# N575F145_v1 register map
File version: 1.0
Registers are 32-bit, read-write, reset 0x0 unless marked. A register's access mark holds for its fields unless they carry their own. Offsets are from the block's base; [hi:lo] are bit positions; 'fields as' and 'values as' point back to an identical list.

## CLK — CLK Register Map
Base 0x50000200
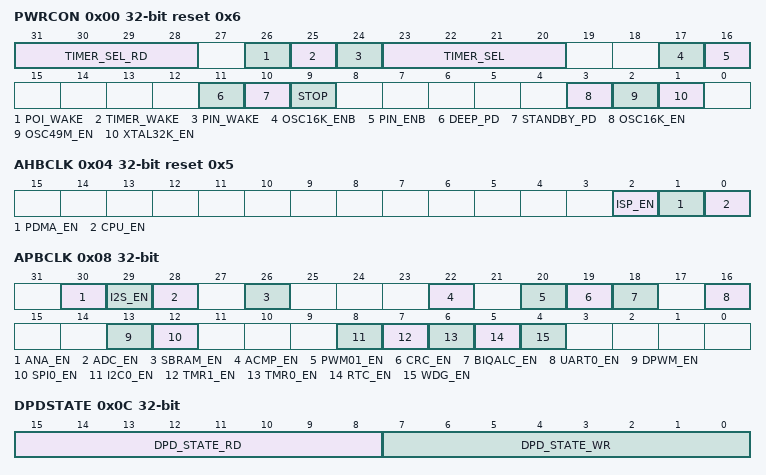
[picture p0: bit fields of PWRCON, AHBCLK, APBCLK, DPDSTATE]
0x00 PWRCON reset 0x6 (reset mask 0xFFFFFF) — System Power Control Register
  [31:28] TIMER_SEL_RD — Current Wakeup Timer Setting. Read-Only. Read back of the current WAKEUP timer setting. This value is updated with TIMER_SEL upon entering DPD mode.
  [26] POI_WAKE — POI Wakeup Flag. Read Only. This flag indicates that wakeup of device was requested with a power-on reset. Flag is cleared when DPD mode is entered.
  [25] TIMER_WAKE — Timer Wakeup Flag. Read Only. This flag indicates that wakeup of device was requested with TIMER count of the 16Khz oscillator. Flag is cleared when DPD mode is entered.
  [24] PIN_WAKE — Pin Wakeup Flag. Read Only. This flag indicates that wakeup of device was requested with a high to low transition of the WAKEUP pin. Flag is cleared when DPD mode is entered.
  [23:20] TIMER_SEL — Select Wakeup Timer. TIMER_SEL[0] = 1: WAKEUP after 128 OSC16K clocks (12.8 ms). TIMER_SEL[1] = 1: WAKEUP after 256 OSC16K clocks (25.6 ms). TIMER_SEL[2] = 1: WAKEUP after 512 OSC16K clocks (51.2 ms). TIMER_SEL[3] = 1: WAKEUP after 1024 OSC16K clocks (102.4ms)
  [17] OSC16K_ENB — OSC16K Enabled Control. Determines whether OSC16K is enabled in DPD mode. If OSC16K is disabled, device cannot wake from DPD with TIMER_SEL delay.
    0=enabled; 1=disabled
  [16] PIN_ENB — Wakeup Pin Enabled Control. Determines whether WAKEUP pin is enabled in DPD mode.
    0=enabled; 1=disabled
  [11] DEEP_PD — Deep Power Down (DPD) Bit. Set to '1' and issue WFI/WFE instruction to enter DPD mode.
  [10] STANDBY_PD — Standby Power Down (SPD) Bit. Set to '1' and issue WFI/WFE instruction to enter SPD mode.
  [9] STOP — Stop. Reserved - do not set to '1'
  [3] OSC16K_EN — OSC16K Oscillator Enable Bit
    0=disable; 1=enable (default)
  [2] OSC49M_EN — OSC49M Oscillator Enable Bit
    0=disable; 1=enable (default)
  [1] XTAL32K_EN — External 32.768 kHz Crystal Enable Bit
    0=disable (default); 1=enable
0x04 AHBCLK reset 0x5 — AHB Device Clock Enable Control Register
  [2] ISP_EN — Flash ISP Controller Clock Enable Control
    0=To disable the Flash ISP engine clock; 1=To enable the Flash ISP engine clock
  [1] PDMA_EN — PDMA Controller Clock Enable Control
    0=To disable the PDMA engine clock; 1=To enable the PDMA engine clock
  [0] CPU_EN — CPU Clock Enable (HCLK). Must be left as '1' for normal operation.
0x08 APBCLK — APB Device Clock Enable Control Register
  [all] fields
    0=Disable; 1=Enable
  [30] ANA_EN — Analog Block Clock Enable Control
  [29] I2S_EN — I2S Clock Enable Control
  [28] ADC_EN — Audio Analog-Digital-Converter (ADC) Clock Enable Control
  [26] SBRAM_EN — Standby RAM Clock Enable Control
  [22] ACMP_EN — Analog Comparator Clock Enable Control
  [20] PWM01_EN — PWM Block Clock Enable Control
  [19] CRC_EN — Cyclic Redundancy Check Block Clock Enable Control
  [18] BIQALC_EN — Biquad Filter And Automatic Level Control Block Clock Enable Control
  [16] UART0_EN — UART0 Clock Enable Control
  [13] DPWM_EN — Differential PWM Speaker Driver Clock Enable Control
  [12] SPI0_EN — SPI0 Clock Enable Control
  [8] I2C0_EN — I2C0 Clock Enable Control
  [7] TMR1_EN — Timer1 Clock Enable Control
  [6] TMR0_EN — Timer0 Clock Enable Control
  [5] RTC_EN — Real-Time-Clock APB Interface Clock Control
  [4] WDG_EN — Watchdog Clock Enable Control
0x0C DPDSTATE (reset mask 0xFFFF00FF) — Deep Power Down State Register
  [15:8] DPD_STATE_RD — DPD State Read Back. Read back of DPDSTATE register. This register was preserved from last DPD event .
  [7:0] DPD_STATE_WR — DPD State Write. To set the DPDSTATE register, write value to this register. Data is latched on next DPD event.
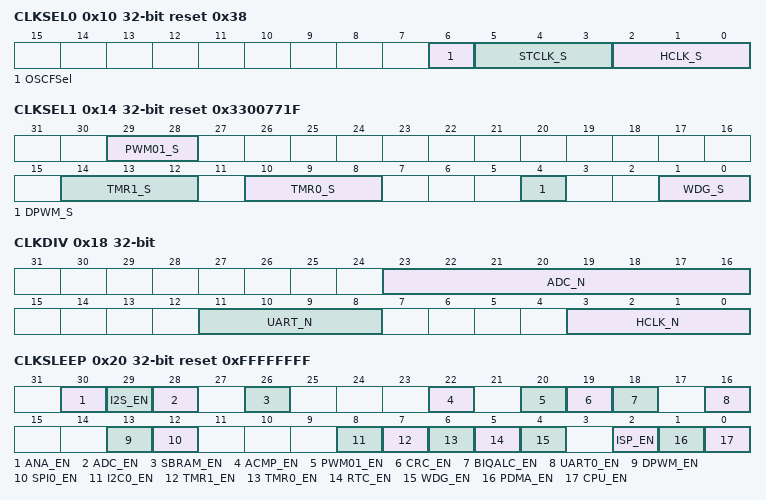
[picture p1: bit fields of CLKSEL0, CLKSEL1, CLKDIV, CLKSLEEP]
0x10 CLKSEL0 reset 0x38 — Clock Source Select Control Register 0
  [6] OSCFSel — OSC48M Frequency Select. Determines which trim setting to use for OSC48M internal oscillator. Oscillator is factory trimmed within 1% to:
    0=49.152MHz (Default); 1=32.768MHz
  [5:3] STCLK_S — MCU Cortex_M0 SysTick Clock Source Select. These bits are protected, to write to bits first perform the unlock sequence (see Protected Register Lock Key Register (REGLOCK)). 000 = clock source from 16 kHz internal clock. 001 = clock source from external 32kHz crystal clock. 010 = clock source from 16 kHz internal oscillator divided by 2. 011 = clock source from OSC49M internal oscillator divided by 2. 1xx = clock source from HCLK / 2 (Default). Note that to use STCLK_S as source of SysTic timer the CLKSRC bit of SysTick->CTRL must be set to 0.
  [2:0] HCLK_S — HCLK Clock Source Select. Ensure that related clock sources (pre-select and new-select) are enabled before updating register. These bits are protected, to write to bits first perform the unlock sequence (see Protected Register Lock Key Register (REGLOCK)). 000 = clock source from internal OSC48M oscillator. 001 = clock source from external 32kHz crystal clock. 010 = clock source from internal 16 kHz oscillator clock. Others = reserved
0x14 CLKSEL1 reset 0x3300771F — Clock Source Select Control Register 1
  [29:28] PWM01_S — PWM0 And PWM1 Clock Source Select. PWM0 and PWM1 uses the same clock source, and prescaler
    0=clock source from internal 16 kHz oscillator; 1=clock source from external 32kHz crystal clock; 2=clock source from HCLK; 3=clock source from internal OSC48M oscillator clock
  [14:12] TMR1_S — TIMER1 Clock Source Select. 000 = clock source from internal 16 kHz oscillator. 001 = clock source from external 32kHz crystal clock. 010 = clock source from HCLK. 011 = clock source from external pin (GPIOA[15]). 1xx = clock source from internal OSC48M oscillator clock
  [10:8] TMR0_S — TIMER0 Clock Source Select. 000 = clock source from internal 16 kHz oscillator. 001 = clock source from external 32kHz crystal clock. 010 = clock source from HCLK. 011 = clock source from external pin (GPIOA[14]). 1xx = clock source from internal OSC48M oscillator clock
  [4] DPWM_S — Differential Speaker Driver PWM Clock Source Select
    0=OSC48M clock; 1=2x OSC48M clock
  [1:0] WDG_S — WDG CLK Clock Source Select
    0=clock source from internal OSC48M oscillator clock; 1=clock source from external 32kHz crystal clock; 2=clock source from HCLK/2048 clock; 3=clock source from internal 16 kHz oscillator clock
0x18 CLKDIV — Clock Divider Number Register
  [23:16] ADC_N — ADC Clock Divide Number From ADC Clock Source. The ADC clock frequency = (ADC clock source frequency ) / (ADC_N + 1)
  [11:8] UART_N — UART Clock Divide Number From UART Clock Source. The UART clock frequency = (UART clock source frequency ) / (UART_N + 1)
  [3:0] HCLK_N — HCLK Clock Divide Number From HCLK Clock Source. The HCLK clock frequency = (HCLK clock source frequency) / (HCLK_N + 1)
0x1C CLKSEL2 reset 0xFFFFFFF0 (reset mask 0xFFFFFFF0) — Clock Source Select Control Register 2
  [1:0] I2S_S — I2S Clock Source Select
    values as CLKSEL1.PWM01_S
0x20 CLKSLEEP reset 0xFFFFFFFF — Sleep Clock Source Select Register
  [all] fields
    0=Disable; 1=Enable
  [30] ANA_EN — Analog Block Sleep Clock Enable Control
  [29] I2S_EN — I2S Sleep Clock Enable Control
  [28] ADC_EN — Audio Analog-Digital-Converter (ADC) Sleep Clock Enable Control
  [26] SBRAM_EN — Standby RAM Sleep Clock Enable Control
  [22] ACMP_EN — Analog Comparator Sleep Clock Enable Control
  [20] PWM01_EN — PWM Block Sleep Clock Enable Control
  [19] CRC_EN — Cyclic Redundancy Check Sleep Block Clock Enable Control
  [18] BIQALC_EN — Biquad filter/ALC block Sleep Clock Enable Control
  [16] UART0_EN — UART0 Sleep Clock Enable Control
  [13] DPWM_EN — Differential PWM Speaker Driver Sleep Clock Enable Control
  [12] SPI0_EN — SPI0 Sleep Clock Enable Control
  [8] I2C0_EN — I2C0 Sleep Clock Enable Control
  [7] TMR1_EN — Timer1 Sleep Clock Enable Control
  [6] TMR0_EN — Timer0 Sleep Clock Enable Control
  [5] RTC_EN — Real-Time- Sleep Clock APB Interface Clock Control
  [4] WDG_EN — Watchdog Sleep Clock Enable Control
  [2] ISP_EN — Flash ISP Controller Sleep Clock Enable Control
  [1] PDMA_EN — PDMA Controller Sleep Clock Enable Control
  [0] CPU_EN — CPU Clock Sleep Enable (HCLK). Must be left as '1' for normal operation.
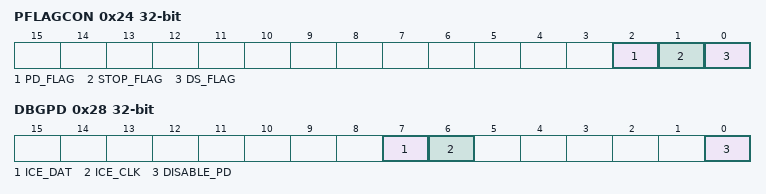
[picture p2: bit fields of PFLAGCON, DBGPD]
0x24 PFLAGCON — Power State Flag Register
  [2] PD_FLAG — Powered Down Flag. This flag is set if core logic was powered down to Standby (SPD). Write '1' to clear flag.
  [1] STOP_FLAG — Stop Flag. This flag is set if core logic was stopped but not powered down. Write '1' to clear flag.
  [0] DS_FLAG — Deep Sleep Flag. This flag is set if core logic was placed in Deep Sleep mode. Write '1' to clear flag.
0x28 DBGPD (reset mask 0xFFFFFF00) — Debug Port Power Down Disable Register
  [7] ICE_DAT — ICE_DAT Pin State. Read Only. Current state of ICE_DAT pin.
  [6] ICE_CLK — ICE_CLK Pin State. Read Only. Current state of ICE_CLK pin.
  [0] DISABLE_PD — Disable Power Down
    0=Enable power down requests; 1=Disable power down requests
